# cslr_dmac5510_001 register map
Vendor: Texas Instruments
Peripheral module from a debugger description file.
Registers are 16-bit, read-write, no defined reset value unless marked. A register's access mark holds for its fields unless they carry their own. Offsets are as the file gives them; lines under a group give offsets from that group; [hi:lo] are bit positions; {n}, {i} and the like mark numbered series; 'fields as' and 'values as' point back to an identical list; <NAME> marks a mode.

## DMA — Direct Memory Access
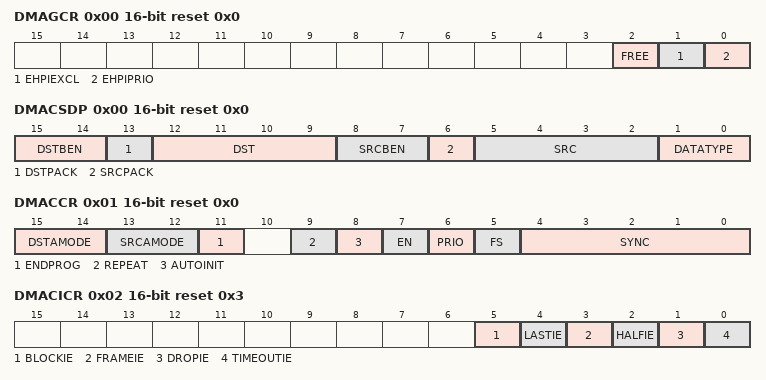
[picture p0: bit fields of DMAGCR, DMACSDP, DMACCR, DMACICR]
0x00 DMAGCR access per field reset 0x0 — Global control register (only one)
  [2] FREE rw — Emulation mode bit.
    0=A breakpoint suspends DMA transfers; 1=DMA transfers continue uninterrupted when a breakpoint occurs
  [1] EHPIEXCL rw — HPI exclusive access bit.
    0=The HPI shares the internal RAM with the DMA channels; 1=The HPI has exclusive access to the internal RAM
  [0] EHPIPRIO rw — HPI priority bit.
    0=Low priority level; 1=High priority level
0x00 DMACSDP reset 0x0 — Source and Destination Parameters Register
  [15:14] DSTBEN — Destination burst enable bits.
    0=00b (Bursting disabled (single access enabled) at the destination.); 1=01b (Bursting disabled (single access enabled) at the destination.); 2=10b (Bursting enabled at the destination.); 3=11b (Reserved (do not use).)
  [13] DSTPACK — Destination packing enable bit.
    0=Packing disabled at the destination; 1=Packing enabled at the destination
  [12:9] DST — Destination selection bits.
    0=0000b (SARAM (single-access RAM inside the DSP).); 1=0001b (DARAM (dual-access RAM inside the DSP).); 2=0010b (External memory (via the external memory interface, EMIF).); 4=0100b (Peripherals (via the peripheral bus controller).)
  [8:7] SRCBEN — Source burst enable bits.
    0=00b (Bursting disabled (single access enabled) at the source.); 1=01b (Bursting disabled (single access enabled) at the source.); 2=10b (Bursting enabled at the source.); 3=11b (Reserved (do not use).)
  [6] SRCPACK — Source packing enable bit.
    0=Packing disabled at the source; 1=Packing enabled at the source
  [5:2] SRC — Source selection bits.
    0=0000b (SARAM (single-access RAM inside the DSP).); 1=0001b (DARAM (dual-access RAM inside the DSP).); 2=0010b (External memory (via the external memory interface, EMIF).); 3=0011b (Peripherals (via the peripheral bus controller).)
  [1:0] DATATYPE — Data type bit.
    0=00b (8-bit.); 1=01b (16-bit.); 2=10b (32-bit.); 3=11b (Reserved (do not use).)
0x01 DMACCR reset 0x0 — Channel Control Register
  [15:14] DSTAMODE — Destination addressing mode bits.
    0=00b (Constant address.); 1=01b (Automatic post increment.); 2=10b (Single index.); 3=11b (Double index (sort).)
  [13:12] SRCAMODE — Source addressing mode bits.
    values as DSTAMODE
  [11] ENDPROG — End-of-programming bit.
    0=Configuration registers ready for programming / Programming in progress; 1=This reserved bit must be kept 0
  [9] REPEAT — Repeat condition bit.
    0=Repeat only if ENDPROG = 1; 1=Repeat regardless of ENDPROG
  [8] AUTOINIT — Auto-initialization bit.
    0=Auto-initialization is disabled; 1=Auto-initialization is enabled
  [7] EN — Channel enable bit.
    0=The channel is disabled; 1=The channel is enabled
  [6] PRIO — Channel priority bit.
    0=Low priority; 1=High priority
  [5] FS — Frame/element synchronization bit.
    0=Element synchronization; 1=Frame synchronization
  [4:0] SYNC — Synchronization control bits.
0x02 DMAGSCR access per field reset 0x0 — Global software compatibility register (only one)
  [0] DINDXMD rw — Destination element and frame index mode bit.
    0=Compatibility mode; 1=Enhanced mode
0x02 DMACICR access per field reset 0x3 — Interrupt Control Register
  [5] BLOCKIE rw — Whole block interrupt enable bit.
    0=Do not record the event; 1=Set the BLOCK bit and send the channel interrupt request to the CPU
  [4] LASTIE rw — Last frame interrupt enable bit.
    0=Do not record the event; 1=Set the LAST bit and send the channel interrupt request to the CPU
  [3] FRAMEIE rw — Whole frame interrupt enable bit.
    0=Do not record the event; 1=Set the FRAME bit and send the channel interrupt request to the CPU
  [2] HALFIE rw — Half frame interrupt enable bit.
    0=Do not record the event; 1=Set the HALF bit and send the channel interrupt request to the CPU
  [1] DROPIE rw — Synchronization event drop interrupt enable bit.
    0=Do not record the drop; 1=Set the DROP bit and send the channel interrupt request to the CPU
  [0] TIMEOUTIE rw — Time-out interrupt enable bit.
    0=Do not record the time-out error; 1=Set the TIMEOUT bit and send the bus-error interrupt request to the CPU
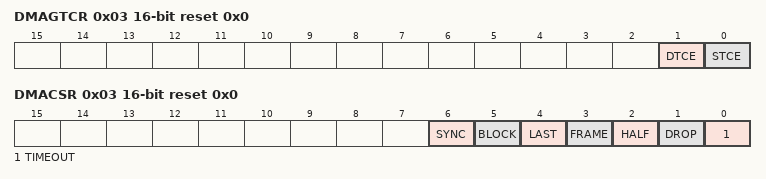
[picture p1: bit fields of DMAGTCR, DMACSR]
0x03 DMAGTCR access per field reset 0x0 — Global Time-Out Control Register
  [1] DTCE rw — DARAM time-out counter enable bit.
    0=DARAM time-out counter disabled; 1=DARAM time-out counter enabled
  [0] STCE rw — SARAM time-out counter enable bit.
    0=SARAM time-out counter disabled; 1=SARAM time-out counter enabled
0x03 DMACSR ro reset 0x0 — Status Register
  [6] SYNC — Synchronization event status bit.
    0=The DMA controller has finished servicing the previous access request; 1=The synchronization event has occurred
  [5] BLOCK — Whole block status bit.
    0=The whole-block event has not occurred yet, or BLOCK has been cleared; 1=The whole block has been transferred
  [4] LAST — Last frame status bit.
    0=The last-frame event has not occurred yet, or LAST has been cleared; 1=The DMA controller has started transferring the last frame
  [3] FRAME — Whole frame status bit.
    0=The whole-frame event has not occurred yet, or FRAME has been cleared; 1=The whole frame has been transferred
  [2] HALF — Half frame status bit.
    0=The half-frame event has not occurred yet, or HALF has been cleared; 1=The first half of the frame has been transferred
  [1] DROP — Synchronization event drop status bit.
    0=A synchronization event drop has not occurred, or DROP has been cleared; 1=A synchronization event drop has occurred
  [0] TIMEOUT — Time-out status bit.
    0=A time-out error has not occurred, or TIMEOUT has been cleared; 1=A time-out error has occurred
0x04 DMACSSAL — Source Start Address Registers
  [15:0] SSAL — Lower part of source start address (byte address).
0x05 DMACSSAU — Source Start Address Registers
  [15:0] SSAU — Upper part of source start address (byte address).
0x06 DMACDSAL — Destination Start Address Registers
  [15:0] DSAL — Lower part of destination start address (byte address).
0x07 DMACDSAU — Destination Start Address Registers
  [15:0] DSAU — Upper part of destination start address (byte address).
0x08 DMACEN — Element Number Register
  [15:0] ELEMENTNUM
    0=0000h (Reserved (do not use).)
0x09 DMACFN — Frame Number Register
  [15:0] FRAMENUM
    0=0000h (Reserved (do not use).)
0x0A DMACEI/DMACSEI — Element Index Registers
  [15:0] ELEMENTNDX
0x0A DMACFI/DMACSFI — Frame Index Registers
  [15:0] FRAMENDX
0x0C DMACSAC — Source Address Counter
  [15:0] SAC — Low 16 bits of current source address.
0x0D DMACDAC — Destination Address Counter
  [15:0] DAC — Low 16 bits of the current destination address.
0x0E DMACDEI — Element Index Registers
  [15:0] ELEMENTNDX
0x0F DMACDFI — Frame Index Registers
  [15:0] FRAMENDX
